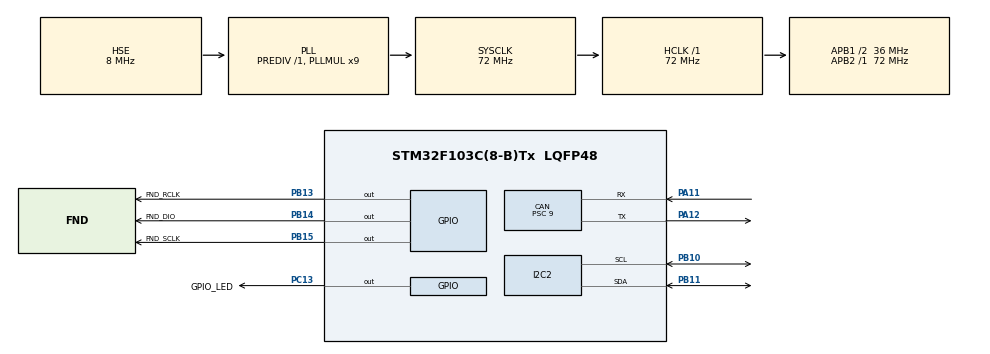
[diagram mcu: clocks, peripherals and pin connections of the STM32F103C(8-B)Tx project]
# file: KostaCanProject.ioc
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CAN.BS1=CAN_BS1_5TQ
CAN.BS2=CAN_BS2_2TQ
CAN.CalculateBaudRate=500000
CAN.CalculateTimeBit=2000
CAN.CalculateTimeQuantum=250.0
CAN.Prescaler=9
FREERTOS.Tasks01=defaultTask,0,256,StartDefaultTask,Default,NULL,Dynamic,NULL,NULL;myTask02,-3,256,StartTask02,Default,NULL,Dynamic,NULL,NULL
FREERTOS.configUSE_NEWLIB_REENTRANT=1
I2C2.I2C_Mode=I2C_Fast
Mcu.Family=STM32F1
Mcu.Name=STM32F103C(8-B)Tx
Mcu.Package=LQFP48
NVIC.PriorityGroup=NVIC_PRIORITYGROUP_4
NVIC.TIM4_IRQn=true\:15\:0\:false\:false\:true\:false\:false\:true\:true
NVIC.TimeBase=TIM4_IRQn
NVIC.TimeBaseIP=TIM4
NVIC.USB_LP_CAN1_RX0_IRQn=true\:5\:0\:false\:false\:true\:true\:true\:true\:true
PA11.Mode=CAN_Activate
PA11.Signal=CAN_RX
PA12.Mode=CAN_Activate
PA12.Signal=CAN_TX
PA13.Mode=Serial_Wire
PA13.Signal=SYS_JTMS-SWDIO
PA14.Mode=Serial_Wire
PA14.Signal=SYS_JTCK-SWCLK
PB10.Mode=I2C
PB10.Signal=I2C2_SCL
PB11.Mode=I2C
PB11.Signal=I2C2_SDA
PB13.GPIO_Label=FND_RCLK
PB13.GPIO_ModeDefaultOutputPP=GPIO_MODE_OUTPUT_PP
PB13.GPIO_PuPd=GPIO_PULLUP
PB13.GPIO_Speed=GPIO_SPEED_FREQ_HIGH
PB13.PinState=GPIO_PIN_SET
PB13.Signal=GPIO_Output
PB14.GPIO_Label=FND_DIO
PB14.GPIO_ModeDefaultOutputPP=GPIO_MODE_OUTPUT_PP
PB14.GPIO_PuPd=GPIO_PULLUP
PB14.GPIO_Speed=GPIO_SPEED_FREQ_HIGH
PB14.PinState=GPIO_PIN_SET
PB14.Signal=GPIO_Output
PB15.GPIO_Label=FND_SCLK
PB15.GPIO_PuPd=GPIO_PULLUP
PB15.GPIO_Speed=GPIO_SPEED_FREQ_HIGH
PB15.PinState=GPIO_PIN_SET
PB15.Signal=GPIO_Output
PC13-TAMPER-RTC.GPIO_Label=GPIO_LED
PC13-TAMPER-RTC.GPIO_ModeDefaultOutputPP=GPIO_MODE_OUTPUT_PP
PC13-TAMPER-RTC.GPIO_PuPd=GPIO_PULLUP
PC13-TAMPER-RTC.GPIO_Speed=GPIO_SPEED_FREQ_HIGH
PC13-TAMPER-RTC.PinState=GPIO_PIN_SET
PC13-TAMPER-RTC.Signal=GPIO_Output
PD0-OSC_IN.Mode=HSE-External-Oscillator
PD0-OSC_IN.Signal=RCC_OSC_IN
PD1-OSC_OUT.Mode=HSE-External-Oscillator
PD1-OSC_OUT.Signal=RCC_OSC_OUT
ProjectManager.HeapSize=0x200
ProjectManager.StackSize=0x400
ProjectManager.TargetToolchain=STM32CubeIDE
RCC.AHBFreq_Value=72000000
RCC.APB1CLKDivider=RCC_HCLK_DIV2
RCC.APB1Freq_Value=36000000
RCC.APB1TimFreq_Value=72000000
RCC.APB2Freq_Value=72000000
RCC.APB2TimFreq_Value=72000000
RCC.HCLKFreq_Value=72000000
RCC.PLLMUL=RCC_PLL_MUL9
RCC.PLLSourceVirtual=RCC_PLLSOURCE_HSE
RCC.SYSCLKFreq_VALUE=72000000
RCC.SYSCLKSource=RCC_SYSCLKSOURCE_PLLCLK
RCC.USBFreq_Value=72000000
VP_FREERTOS_VS_CMSIS_V1.Mode=CMSIS_V1
VP_SYS_VS_tim4.Mode=TIM4
board=custom

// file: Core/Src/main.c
/* USER CODE BEGIN Header */
/**
  ******************************************************************************
  * @file           : main.c
  * @brief          : Main program body
  ******************************************************************************
  * @attention
  *
  * Copyright (c) 2024 STMicroelectronics.
  * All rights                         reserved.
  *
  * This software is licensed under terms that can be found in the LICENSE file
  * in the root directory of this software component.
  * If no LICENSE file comes with this software, it is provided AS-IS.
  *
  ******************************************************************************
  */
/* USER CODE END Header */
#include "main.h"
#include "cmsis_os.h"
#include "can.h"
#include "i2c.h"
#include "gpio.h"

/* USER CODE BEGIN Includes */
#include "fnd_controller.h"
#include "ssd1306.h"
#include "fonts.h"
#include "bitmap.h"
#include "horse_anim.h"
/* USER CODE END Includes */

/* USER CODE BEGIN PV */
extern uint8_t _LED_0F[29];
//extern I2C_HandleTypeDef hi2c2;
/* USER CODE END PV */

void SystemClock_Config(void);
void MX_FREERTOS_Init(void);

int main(void)
{

  /* MCU Configuration--------------------------------------------------------*/

  /* Reset of all peripherals, Initializes the Flash interface and the Systick. */
  HAL_Init();

  /* Configure the system clock */
  SystemClock_Config();

  /* Initialize all configured peripherals */
  MX_GPIO_Init();
  MX_CAN_Init();
  MX_I2C2_Init();
  /* USER CODE BEGIN 2 */

  FND_INIT();
  SSD1306_Init();

  /* USER CODE END 2 */

  /* Call init function for freertos objects (in cmsis_os2.c) */
  //MX_FREERTOS_Init();

  /* Start scheduler */
  //osKernelStart();

  /* We should never get here as control is now taken by the scheduler */

  /* Infinite loop */
  while (1)
  {

  }
}

void SystemClock_Config(void)
{
  RCC_OscInitTypeDef RCC_OscInitStruct = {0};
  RCC_ClkInitTypeDef RCC_ClkInitStruct = {0};

  /** Initializes the RCC Oscillators according to the specified parameters
  * in the RCC_OscInitTypeDef structure.
  */
  RCC_OscInitStruct.OscillatorType = RCC_OSCILLATORTYPE_HSE;
  RCC_OscInitStruct.HSEState = RCC_HSE_ON;
  RCC_OscInitStruct.HSEPredivValue = RCC_HSE_PREDIV_DIV1;
  RCC_OscInitStruct.HSIState = RCC_HSI_ON;
  RCC_OscInitStruct.PLL.PLLState = RCC_PLL_ON;
  RCC_OscInitStruct.PLL.PLLSource = RCC_PLLSOURCE_HSE;
  RCC_OscInitStruct.PLL.PLLMUL = RCC_PLL_MUL9;
  if (HAL_RCC_OscConfig(&RCC_OscInitStruct) != HAL_OK)
  {
    Error_Handler();
  }

  /** Initializes the CPU, AHB and APB buses clocks
  */
  RCC_ClkInitStruct.ClockType = RCC_CLOCKTYPE_HCLK|RCC_CLOCKTYPE_SYSCLK
                              |RCC_CLOCKTYPE_PCLK1|RCC_CLOCKTYPE_PCLK2;
  RCC_ClkInitStruct.SYSCLKSource = RCC_SYSCLKSOURCE_PLLCLK;
  RCC_ClkInitStruct.AHBCLKDivider = RCC_SYSCLK_DIV1;
  RCC_ClkInitStruct.APB1CLKDivider = RCC_HCLK_DIV2;
  RCC_ClkInitStruct.APB2CLKDivider = RCC_HCLK_DIV1;

  if (HAL_RCC_ClockConfig(&RCC_ClkInitStruct, FLASH_LATENCY_2) != HAL_OK)
  {
    Error_Handler();
  }
}

void HAL_TIM_PeriodElapsedCallback(TIM_HandleTypeDef *htim)
{
  if (htim->Instance == TIM4) {
    HAL_IncTick();
  }
}

void Error_Handler(void)
{
  __disable_irq();
  while (1)
  {
  }
}
